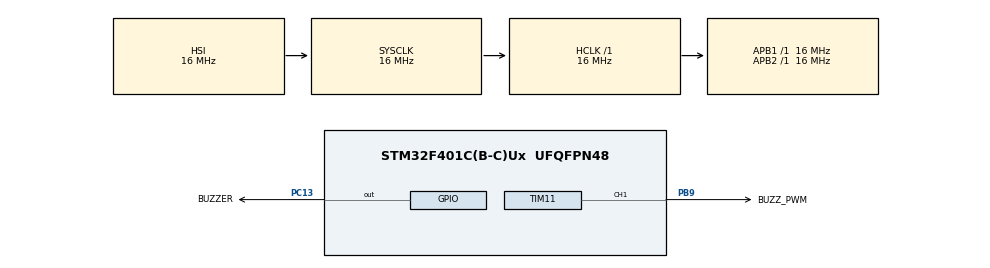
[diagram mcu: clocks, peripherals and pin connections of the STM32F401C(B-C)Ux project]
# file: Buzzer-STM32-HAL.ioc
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Mcu.Family=STM32F4
Mcu.Name=STM32F401C(B-C)Ux
Mcu.Package=UFQFPN48
NVIC.PriorityGroup=NVIC_PRIORITYGROUP_4
PA13.Mode=Serial_Wire
PA13.Signal=SYS_JTMS-SWDIO
PA14.Mode=Serial_Wire
PA14.Signal=SYS_JTCK-SWCLK
PB9.GPIO_Label=BUZZ_PWM
PB9.Signal=S_TIM11_CH1
PC13-ANTI_TAMP.GPIO_Label=BUZZER
PC13-ANTI_TAMP.Signal=GPIO_Output
ProjectManager.HeapSize=0x200
ProjectManager.StackSize=0x400
ProjectManager.TargetToolchain=STM32CubeIDE
RCC.AHBFreq_Value=16000000
RCC.APB1Freq_Value=16000000
RCC.APB2Freq_Value=16000000
RCC.CortexFreq_Value=16000000
RCC.HSE_VALUE=25000000
RCC.HSI_VALUE=16000000
RCC.LSE_VALUE=32768
RCC.SYSCLKFreq_VALUE=16000000
RCC.VCOOutputFreq_Value=192000000
SH.S_TIM11_CH1.0=TIM11_CH1,PWM Generation1 CH1
TIM11.Channel=TIM_CHANNEL_1
TIM11.Period=1000-1
TIM11.Prescaler=8-1
VP_TIM11_VS_ClockSourceINT.Mode=Enable_Timer
board=custom

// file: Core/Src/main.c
/* USER CODE BEGIN Header */
/**
  ******************************************************************************
  * @file           : main.c
  * @brief          : Main program body
  ******************************************************************************
  * @attention
  *
  * Copyright (c) 2022 STMicroelectronics.
  * All rights reserved.
  *
  * This software is licensed under terms that can be found in the LICENSE file
  * in the root directory of this software component.
  * If no LICENSE file comes with this software, it is provided AS-IS.
  *
  ******************************************************************************
  */
/* USER CODE END Header */
#include "main.h"

/* USER CODE BEGIN Includes */
#include "buzzer.h"
/* USER CODE END Includes */

TIM_HandleTypeDef htim11;

void SystemClock_Config(void);
static void MX_GPIO_Init(void);
static void MX_TIM11_Init(void);

int main(void)
{

  /* MCU Configuration--------------------------------------------------------*/

  /* Reset of all peripherals, Initializes the Flash interface and the Systick. */
  HAL_Init();

  /* Configure the system clock */
  SystemClock_Config();

  /* Initialize all configured peripherals */
  MX_GPIO_Init();
  MX_TIM11_Init();
  /* USER CODE BEGIN 2 */

  BUZZER_Init(BUZ_ACTIVE, &htim11, TIM_CHANNEL_1);

  BUZZER_Go(TBUZ_100, TICK_2);
  HAL_Delay(2000);

  /* USER CODE END 2 */

  /* Infinite loop */
  /* USER CODE BEGIN WHILE */
  while (1)
  {

    BUZZER_Go(TBUZ_50, TICK_4);
    HAL_Delay(2000);

    /* USER CODE END WHILE */

  }
}

void SystemClock_Config(void)
{
  RCC_OscInitTypeDef RCC_OscInitStruct = {0};
  RCC_ClkInitTypeDef RCC_ClkInitStruct = {0};

  /** Configure the main internal regulator output voltage
  */
  __HAL_RCC_PWR_CLK_ENABLE();
  __HAL_PWR_VOLTAGESCALING_CONFIG(PWR_REGULATOR_VOLTAGE_SCALE2);

  /** Initializes the RCC Oscillators according to the specified parameters
  * in the RCC_OscInitTypeDef structure.
  */
  RCC_OscInitStruct.OscillatorType = RCC_OSCILLATORTYPE_HSI;
  RCC_OscInitStruct.HSIState = RCC_HSI_ON;
  RCC_OscInitStruct.HSICalibrationValue = RCC_HSICALIBRATION_DEFAULT;
  RCC_OscInitStruct.PLL.PLLState = RCC_PLL_NONE;
  if (HAL_RCC_OscConfig(&RCC_OscInitStruct) != HAL_OK)
  {
    Error_Handler();
  }

  /** Initializes the CPU, AHB and APB buses clocks
  */
  RCC_ClkInitStruct.ClockType = RCC_CLOCKTYPE_HCLK|RCC_CLOCKTYPE_SYSCLK
                              |RCC_CLOCKTYPE_PCLK1|RCC_CLOCKTYPE_PCLK2;
  RCC_ClkInitStruct.SYSCLKSource = RCC_SYSCLKSOURCE_HSI;
  RCC_ClkInitStruct.AHBCLKDivider = RCC_SYSCLK_DIV1;
  RCC_ClkInitStruct.APB1CLKDivider = RCC_HCLK_DIV1;
  RCC_ClkInitStruct.APB2CLKDivider = RCC_HCLK_DIV1;

  if (HAL_RCC_ClockConfig(&RCC_ClkInitStruct, FLASH_LATENCY_0) != HAL_OK)
  {
    Error_Handler();
  }
}

static void MX_TIM11_Init(void)
{

  TIM_OC_InitTypeDef sConfigOC = {0};

  htim11.Instance = TIM11;
  htim11.Init.Prescaler = 8-1;
  htim11.Init.CounterMode = TIM_COUNTERMODE_UP;
  htim11.Init.Period = 1000-1;
  htim11.Init.ClockDivision = TIM_CLOCKDIVISION_DIV1;
  htim11.Init.AutoReloadPreload = TIM_AUTORELOAD_PRELOAD_DISABLE;
  if (HAL_TIM_Base_Init(&htim11) != HAL_OK)
  {
    Error_Handler();
  }
  if (HAL_TIM_PWM_Init(&htim11) != HAL_OK)
  {
    Error_Handler();
  }
  sConfigOC.OCMode = TIM_OCMODE_PWM1;
  sConfigOC.Pulse = 0;
  sConfigOC.OCPolarity = TIM_OCPOLARITY_HIGH;
  sConfigOC.OCFastMode = TIM_OCFAST_DISABLE;
  if (HAL_TIM_PWM_ConfigChannel(&htim11, &sConfigOC, TIM_CHANNEL_1) != HAL_OK)
  {
    Error_Handler();
  }
  HAL_TIM_MspPostInit(&htim11);

}

static void MX_GPIO_Init(void)
{
  GPIO_InitTypeDef GPIO_InitStruct = {0};

  /* GPIO Ports Clock Enable */
  __HAL_RCC_GPIOC_CLK_ENABLE();
  __HAL_RCC_GPIOA_CLK_ENABLE();
  __HAL_RCC_GPIOB_CLK_ENABLE();

  /*Configure GPIO pin Output Level */
  HAL_GPIO_WritePin(BUZZER_GPIO_Port, BUZZER_Pin, GPIO_PIN_RESET);

  /*Configure GPIO pin : BUZZER_Pin */
  GPIO_InitStruct.Pin = BUZZER_Pin;
  GPIO_InitStruct.Mode = GPIO_MODE_OUTPUT_PP;
  GPIO_InitStruct.Pull = GPIO_NOPULL;
  GPIO_InitStruct.Speed = GPIO_SPEED_FREQ_LOW;
  HAL_GPIO_Init(BUZZER_GPIO_Port, &GPIO_InitStruct);

}

/* USER CODE BEGIN 4 */

/*** SYSTICK (T = 1ms) ***/
/**
  * @brief  SYSTICK callback.
  * @retval None
  */
void HAL_SYSTICK_Callback(void)
{
	BUZZER_Handler();
}

/* USER CODE END 4 */

void Error_Handler(void)
{
  __disable_irq();
  while (1)
  {
  }
}
